# BlueNRG2 register map
Vendor: STMicroelectronics; Series: BlueNRG2; File version: 1.2.1
CPU: CM0 r0p0, little endian, no MPU, no FPU, 2 interrupt priority bits
Registers are 32-bit, read-write, reset 0x0 unless marked. A register's access mark holds for its fields unless they carry their own. Offsets are from the block's base; [hi:lo] are bit positions; 'fields as' and 'values as' point back to an identical list.

## ADC
Base 0x40800000
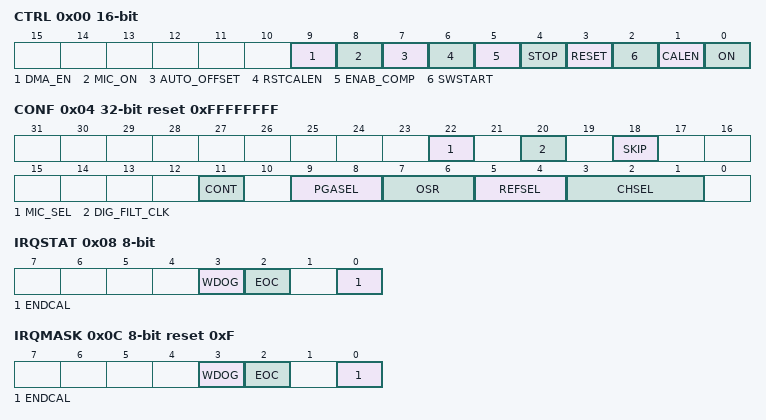
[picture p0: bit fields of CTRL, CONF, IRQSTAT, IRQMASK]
0x00 CTRL 16-bit — ADC control register
  [9] DMA_EN — Enables the DMA.<ul><li>0: DMA is disabled.</li><li>1: DMA is enabled.</li></ul>
    0=DMA_OFF (ADC DMA disable); 1=DMA_ON (ADC DMA enable)
  [8] MIC_ON — Starts ADC analog subsystem only for microphone mode.<ul><li>0: ADC is OFF.</li><li>1: ADC is ON.</li></ul>
    0=MIC_OFF (Filter chain disable); 1=MIC_ON (Filter chain enable)
  [7] AUTO_OFFSET — The automatic calibration routine is enabled if both AUTO_OFFSET and CALEN bitfields are set. The result of the calibration is placed in the OFFSET register according to the SKIP bitfield value.<ul><li>0: disable the automatic calibration.</li><li>1: enable the automatic calibration.</li></ul>This bitfield can be set to 0 only by setting to 1 the bitfield RSTCALEN.
    0=CAL_OFF (ADC automatic calibration disable); 1=CAL_ON (ADC automatic calibration enable)
  [6] RSTCALEN — Disable the calibration phase when set to 1. This bit has to be set to disable the calibration each time calibration is enabled.
    1=RESET (Reset the ADCCALEN bit. Disable the automatic calibration when it is enabled)
  [5] ENAB_COMP — Enables the window comparator when set to 1. WDOG flag is ADC_SR register is set if the converted value is between ADCTHRESHOLD_HI and ADCTHRESHOLD_LO value.
  [4] STOP — Permits to stop the continuous conversion. 1: stop the continuous conversion and switch off the ADC. The bitfields SWSTART, ON, DMA_EN and MIC_ON are auto-cleared if set. This bit is auto-cleared by the hardware so it is always read at 0.
    1=STOP (Stop the continuous mode conversion)
  [3] RESET — Reset all the ADC APB registers when set (CTRL, CONF, DATA_CONV_THRESHOLD_HI, THRESHOLD_LO).
    1=RESET (Reset all the registers content)
  [2] SWSTART — Starts the ADC conversion phase when set. This bit works for all the mode except the microphone mode.
    1=START (Starts the ADC conversion phase when set.)
  [1] CALEN — The automatic calibration routine is enabled if both AUTO_OFFSET and CALEN bitfields are set. The result of the calibration is placed in the OFFSET register according to the SKIP bitfield value.<ul><li>0: disable the automatic calibration.</li><li>1: enable the automatic calibration.</li></ul>This bitfield can be set to 0 only by setting to 1 the bitfield RSTCALEN.
    values as AUTO_OFFSET
  [0] ON — Starts ADC analog subsystem. This bit must be set before starting a conversion.<ul><li>0: ADC is OFF.</li><li>1: ADC is ON.</li></ul>This bit works for all the mode except the microphone mode.
    0=OFF (ADC analog part disable); 1=ON (ADC analog part enable)
0x04 CONF reset 0xFFFFFFFF (reset mask 0xC) — ADC configuration register
  [22] MIC_SEL — Provides the clock on GPIO:<ul><li>0: Do not provided any external clock source.</li><li>1: Provide clock source from GPIO.</li></ul>
    0=DISABLE (Do not provided any external clock source); 1=ENABLE (Provide clock source from GPIO)
  [20] DIG_FILT_CLK — Frequency clock selection value on GPIO0 when MIC_SEL=1:<ul><li>0: 0.8 MHz.</li><li>1: 1.6 MHz.</li></ul>
    0=CLK_0MHz8 (Frequency clock to 0.8 MHz); 1=CLK_1MHz6 (Frequency clock to 1.6 MHz)
  [18] SKIP — It permits to bypass the filter COMP to speed up the conversion for signal at low frequency:<ul><li>0: Filter not bypassed.</li><li>1: Filter bypassed.</li></ul>According to the value of this bitfield, the behaviour of the ADC changes as follows: if SKIP is 0: the first 10 converted samples in ADC mode continuous should be discarded by the user (3 if SKIP is 1). The converted date are in DATA_CONV_MSB (DATA_CONV_LSB if SKIP is 1). The calibration result is in OFFSET_MSB (OFFSET_LSB if SKIP is 1).
    0=FILTER_OFF (Filter for comb not bypassed); 1=FILTER_ON (Filter for comb bypassed)
  [11] CONT — Enable the continuous conversion mode:<ul><li>0: Single conversion.</li><li>1: Continuous conversion.</li></ul>
    0=SINGLE (Single conversion mode); 1=CONT (Continuous conversion mode)
  [9:8] PGASEL — Set the input attenuator value:<ul><li>000b: Input attenuator at 0 dB.</li><li>001b: Input attenuator at 6.02 dB.</li><li>010b: Input attenuator at 9.54 dB.</li></ul>
    0=IN_ATT_0dB0 (Input attenuator at 0 dB); 1=IN_ATT_6dB02 (Input attenuator at 6.02 dB); 2=IN_ATT_9dB54 (Input attenuator at 9.54 dB)
  [7:6] OSR — Set the ADC resolution:<ul><li>00b: Set the oversampling ratio to 200.</li><li>01b: Set the oversampling ratio to 100.</li><li>10b: Set the oversampling ratio to 64.</li><li>11b: Set the oversampling ratio to 32.</li></ul>
    0=Set the oversampling ratio to 200; 1=Set the oversampling ratio to 100; 2=Set the oversampling ratio to 64; 3=Set the oversampling ratio to 32
  [5:4] REFSEL — Set the VREF for single ended conversion:<ul><li>00b: 0.0V.</li><li>10b: 0.6V.</li></ul>
    3=RESEL_0V0 (Set the VREF at 0.0 V); 2=RESEL_0V6 (Set the VREF at 0.6 V)
  [3:1] CHSEL — Select the input channel:<ul><li>000b: All switches open.</li><li>001b: Single ended through ADC2 pin. InP=VREF (internal), InN=ADC2 pin.</li><li>010b: Single ended through ADC1 pin. InP=ADC1 pin, InN=VREF (internal).</li><li>011b: Differential ADC1 pin - ADC2 pin, InP=ADC1 pin, InN=ADC2 pin.</li><li>101b: Battery level detector. InP=0.6V (internal), InN=VBATSENS.</li><li>110b: Short InN=InP=0.6V (internal).</li></ul>
    0=ALL_SWITCH_OPEN; 1=SINGLE_VINP (Single ended InP=ANATEST2 pin, InN=VREF (internal)); 2=SINGLE_VINN (Single ended InN=ANATEST3 pin, InP=VREF (internal)); 3=DIFF_INP_INN (Differential InP=ANATEST2 pin, InN=ANATEST3 pin); 4=TEMP_SENS (InP=VTEMPSENS (internal), InN=0.6V (internal)); 5=BATT_SENS (InP=VBATSENS (internal), InN=0.6V (internal)); 6=SHORT (InP=InN=0.6V (internal))
0x08 IRQSTAT 8-bit ro — IRQ masked status register
  [3] WDOG — 1: when the data is within the thresholds. Clear on register read.
  [2] EOC — 1: when the conversion is completed. Clear on register read.
  [0] ENDCAL — 1: when the calibration is completed. Clear on register read.
0x0C IRQMASK 8-bit reset 0xF — It sets the mask for ADC interrupt
  [3] WDOG — Interrupt mask for the within the threhsold event:<ul><li>0: Interrupt is enabled.</li><li>1: Interrupt is disabled.</li></ul>
  [2] EOC — Interrupt mask for the end of conversion event:<ul><li>0: Interrupt is enabled.</li><li>1: Interrupt is disabled.</li></ul>
  [0] ENDCAL — Interrupt mask for the end of calibration event:<ul><li>0: Interrupt is enabled.</li><li>1: Interrupt is disabled.</li></ul>
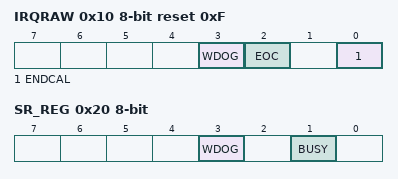
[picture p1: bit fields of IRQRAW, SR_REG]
0x10 IRQRAW 8-bit ro reset 0xF — IRQ status raw register
  [3] WDOG — 1: when the data is inside the thresholds. Clear on register read.
  [2] EOC — 1: when the conversion is completed. Clear on register read.
  [0] ENDCAL — 1: when the calibration is completed. Clear on register read.
0x14 DATA_CONV_LSB 16-bit ro — Result of the conversion LSB in two complement format. If the filter is bypassed, the bitfield SKIP is 1, the DATA_CONV_MSB is negligible and the ADC converted data is the DATA_CONV_LSB * 1.08 (corrective factor). If the filter is not bypassed, the bitfield SKIP is 0, the DATA_CONV_LSB is negligeble.
0x16 DATA_CONV_MSB 16-bit ro — Result of the conversion MSB in two complement format. If the filter is not bypassed, the bitfield SKIP is 0, the DATA_CONV_LSB is negligible and the ADC converted data is the DATA_CONV_MSB. If the filter is bypassed, the bitfield SKIP is 1, the DATA_CONV_MSB is negligeble.
0x18 OFFSET_LSB 16-bit — Offset for correction of converted data. If the bitfield SKIP is 0, the 16-bit offset is in OFFSET_MSB, while if the bitfield SKIP is 1, the 16-bit offset is in OFFSET_LSB.
0x1A OFFSET_MSB 16-bit — Offset for correction of converted data. If the bitfield SKIP is 0, the 16-bit offset is in OFFSET_MSB, while if the bitfield SKIP is 1, the 16-bit offset is in OFFSET_LSB.
0x20 SR_REG 8-bit — ADC status register
  [3] WDOG — If ENAB_COMP=1, this bit indicates the result of the conversion is between high and low threshold:<ul><li>0: DATAOUT[31:0] is NOT between THRESHOLD_HI and THRESHOLD_LO values.</li><li>1: DATAOUT[31:0] is between THRESHOLD_HI and THRESHOLD_LO values.</li></ul>
  [1] BUSY — 1: during conversion.
0x24 THRESHOLD_HI reset 0xFFFFFFFF — High threshold for window comparator
0x28 THRESHOLD_LO reset not defined — Low threshold for window comparator
